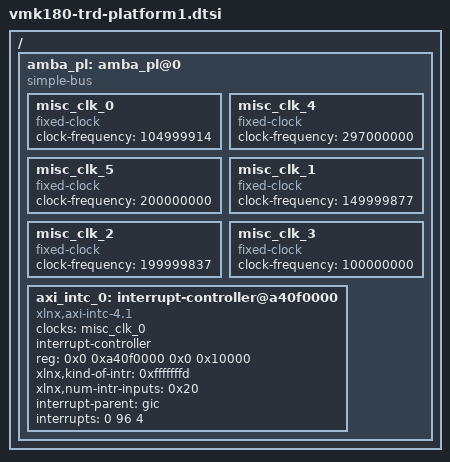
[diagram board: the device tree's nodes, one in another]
/ {
	amba_pl: amba_pl@0 {
		#address-cells = <2>;
		#size-cells = <2>;
		compatible = "simple-bus";
		ranges ;
		misc_clk_0: misc_clk_0 {
			#clock-cells = <0>;
			clock-frequency = <104999914>;
			compatible = "fixed-clock";
		};
		misc_clk_4: misc_clk_4 {
                         #clock-cells = <0>;
                         clock-frequency = <297000000>;
                         compatible = "fixed-clock";
		};
		misc_clk_5: misc_clk_5 {
                         #clock-cells = <0>;
                         clock-frequency = <200000000>;
                         compatible = "fixed-clock";
		};
		misc_clk_1: misc_clk_1 {
			#clock-cells = <0>;
			clock-frequency = <149999877>;
			compatible = "fixed-clock";
		};
                misc_clk_2: misc_clk_2 {
                        #clock-cells = <0>;
                        clock-frequency = <199999837>;
                        compatible = "fixed-clock";
                };
		misc_clk_3: misc_clk_3 {
			#clock-cells = <0>;
			clock-frequency = <100000000>;
			compatible = "fixed-clock";
		};
		axi_intc_0: interrupt-controller@a40f0000 {
		#interrupt-cells = <2>;
		clock-names = "s_axi_aclk";
		clocks = <&misc_clk_0>;
            	compatible = "xlnx,axi-intc-4.1", "xlnx,xps-intc-1.00.a";
       		interrupt-controller ;
		reg = <0x0 0xa40f0000 0x0 0x10000>;
		xlnx,kind-of-intr = <0xfffffffd>;
		xlnx,num-intr-inputs = <0x20>;
		interrupt-names = "irq";
		interrupt-parent = <&gic>;
		interrupts = <0 96 4>;
                };
	};
};

#include "single-capture.dtsi"
#include "display.dtsi"
#include "pcie.dtsi"
#include "ina226-power-monitor.dtsi"
#include "zocl.dtsi"
